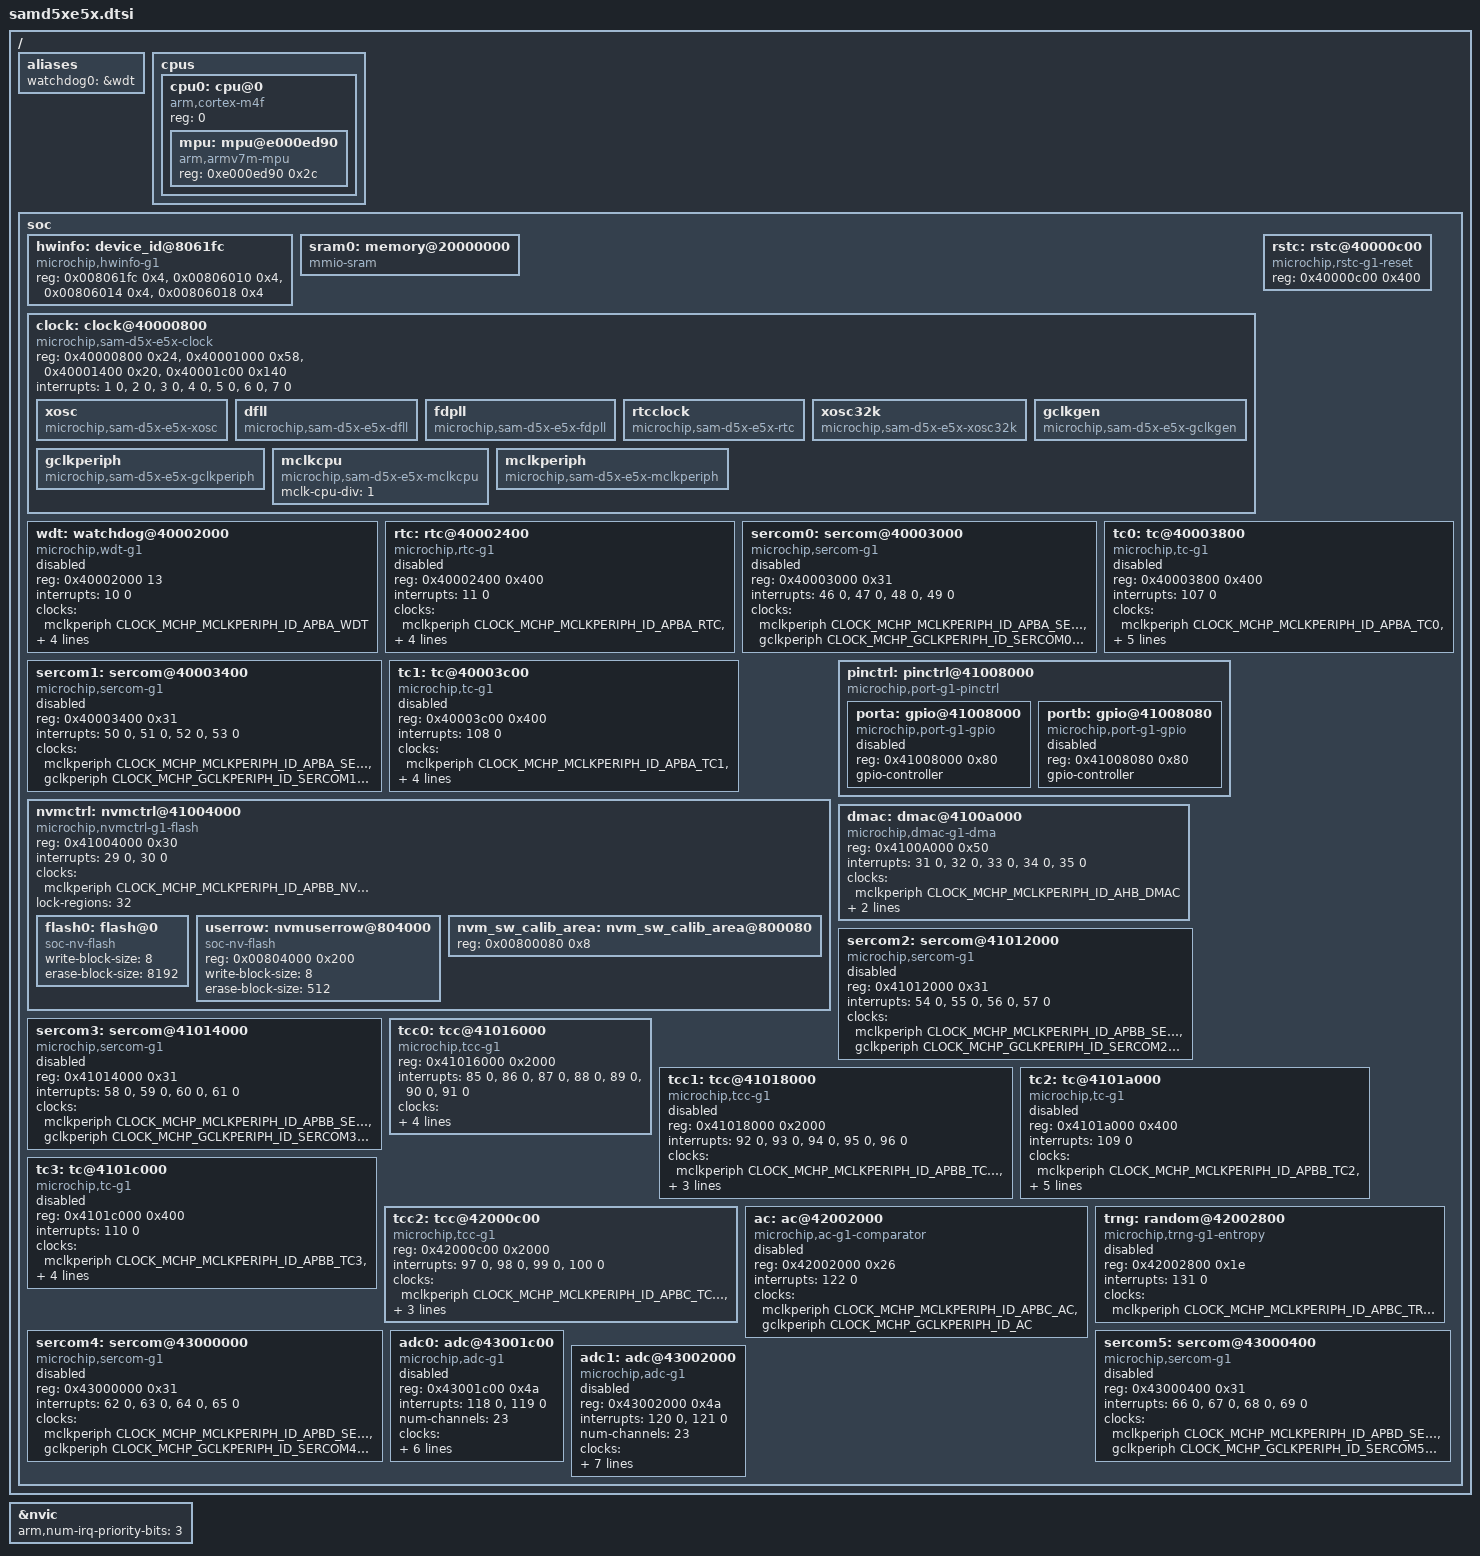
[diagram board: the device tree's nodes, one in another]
/*
 * Copyright (c) 2025-2026 Microchip Technology Inc.
 *
 * SPDX-License-Identifier: Apache-2.0
 */

#include <arm/armv7-m.dtsi>
#include <zephyr/dt-bindings/gpio/gpio.h>
#include <zephyr/dt-bindings/pwm/pwm.h>
#include <zephyr/dt-bindings/clock/mchp_sam_d5x_e5x_clock.h>

/ {
	aliases {
		watchdog0 = &wdt;
	};

	cpus {
		#address-cells = <1>;
		#size-cells = <0>;

		cpu0: cpu@0 {
			device_type = "cpu";
			compatible = "arm,cortex-m4f";
			reg = <0>;
			#address-cells = <1>;
			#size-cells = <1>;

			mpu: mpu@e000ed90 {
				compatible = "arm,armv7m-mpu";
				reg = <0xe000ed90 0x2c>;
			};
		};
	};

	soc {
		hwinfo: device_id@8061fc {
			compatible = "microchip,hwinfo-g1";
			reg = <0x008061fc 0x4>,
			      <0x00806010 0x4>,
			      <0x00806014 0x4>,
			      <0x00806018 0x4>;
		};

		sram0: memory@20000000 {
			compatible = "mmio-sram";
		};

		clock: clock@40000800 {
			compatible = "microchip,sam-d5x-e5x-clock";
			reg = <0x40000800 0x24>, <0x40001000 0x58>,
			      <0x40001400 0x20>, <0x40001c00 0x140>;
			reg-names = "mclk", "oscctrl",
				    "osc32kctrl", "gclk";
			interrupts = <1 0>, <2 0>, <3 0>, <4 0>,
				     <5 0>, <6 0>, <7 0>;
			interrupt-names = "mclk", "xosc0", "xosc1", "dfll",
					  "fdpll0", "fdpll1", "xosc32k";

			xosc: xosc {
				compatible = "microchip,sam-d5x-e5x-xosc";
			};

			dfll: dfll {
				compatible = "microchip,sam-d5x-e5x-dfll";
			};

			fdpll: fdpll {
				compatible = "microchip,sam-d5x-e5x-fdpll";
			};

			rtcclock: rtcclock {
				compatible = "microchip,sam-d5x-e5x-rtc";
				#clock-cells = <1>;
			};

			xosc32k: xosc32k {
				compatible = "microchip,sam-d5x-e5x-xosc32k";
			};

			gclkgen: gclkgen {
				compatible = "microchip,sam-d5x-e5x-gclkgen";
			};

			gclkperiph: gclkperiph {
				compatible = "microchip,sam-d5x-e5x-gclkperiph";
				#clock-cells = <1>;
			};

			mclkcpu: mclkcpu {
				compatible = "microchip,sam-d5x-e5x-mclkcpu";
				mclk-cpu-div = <1>;
			};

			mclkperiph: mclkperiph {
				compatible = "microchip,sam-d5x-e5x-mclkperiph";
				#clock-cells = <1>;
			};
		};

		rstc: rstc@40000c00 {
			compatible = "microchip,rstc-g1-reset";
			reg = <0x40000c00 0x400>;
		};

		wdt: watchdog@40002000 {
			compatible = "microchip,wdt-g1";
			reg = <0x40002000 13>;
			interrupts = <10 0>;
			interrupt-names = "wdt-ew";
			clocks = <&mclkperiph CLOCK_MCHP_MCLKPERIPH_ID_APBA_WDT>;
			clock-names = "mclk";
			max-installable-timeout-count = <1>;
			max-timeout-window = <0x4000>;	/* 16384 milliseconds */
			max-timeout-window-mode = <0x8000>;/* 32768 milliseconds */
			min-window-limit = <0x8>;/* 8 milliseconds */
			status = "disabled";
		};

		rtc: rtc@40002400 {
			compatible = "microchip,rtc-g1";
			reg = <0x40002400 0x400>;
			interrupts = <11 0>;
			clocks = <&mclkperiph CLOCK_MCHP_MCLKPERIPH_ID_APBA_RTC>,
				 <&rtcclock CLOCK_MCHP_RTC_ID>;
			clock-names = "mclk", "rtcclk";
			prescaler = <1>;
			alarms-count = <2>;
			cal-constant = <1048576>;
			status = "disabled";
		};

		sercom0: sercom@40003000 {
			compatible = "microchip,sercom-g1";
			status = "disabled";
			reg = <0x40003000 0x31>;
			interrupts = <46 0>, <47 0>, <48 0>, <49 0>;
			clocks = <&mclkperiph CLOCK_MCHP_MCLKPERIPH_ID_APBA_SERCOM0>,
				 <&gclkperiph CLOCK_MCHP_GCLKPERIPH_ID_SERCOM0_CORE>;
			clock-names = "mclk", "gclk";
		};

		sercom1: sercom@40003400 {
			compatible = "microchip,sercom-g1";
			status = "disabled";
			reg = <0x40003400 0x31>;
			interrupts = <50 0>, <51 0>, <52 0>, <53 0>;
			clocks = <&mclkperiph CLOCK_MCHP_MCLKPERIPH_ID_APBA_SERCOM1>,
				 <&gclkperiph CLOCK_MCHP_GCLKPERIPH_ID_SERCOM1_CORE>;
			clock-names = "mclk", "gclk";
		};

		tc0: tc@40003800 {
			compatible = "microchip,tc-g1";
			reg = <0x40003800 0x400>;
			interrupts = <107 0>;
			clocks = <&mclkperiph CLOCK_MCHP_MCLKPERIPH_ID_APBA_TC0>,
				 <&gclkperiph CLOCK_MCHP_GCLKPERIPH_ID_TC0>,
				 <&mclkperiph CLOCK_MCHP_MCLKPERIPH_ID_APBA_TC1>;
			clock-names = "mclk", "gclk", "client_mclk";
			max-bit-width = <16>;
			prescaler = <1>;
			channels = <2>;
			status = "disabled";
		};

		tc1: tc@40003c00 {
			compatible = "microchip,tc-g1";
			reg = <0x40003c00 0x400>;
			interrupts = <108 0>;
			clocks = <&mclkperiph CLOCK_MCHP_MCLKPERIPH_ID_APBA_TC1>,
				 <&gclkperiph CLOCK_MCHP_GCLKPERIPH_ID_TC1>;
			clock-names = "mclk", "gclk";
			max-bit-width = <16>;
			prescaler = <1>;
			channels = <2>;
			status = "disabled";
		};

		nvmctrl: nvmctrl@41004000 {
			compatible = "microchip,nvmctrl-g1-flash";
			status = "okay";
			reg = <0x41004000 0x30>;
			interrupts = <29 0>, <30 0>;
			clocks = <&mclkperiph CLOCK_MCHP_MCLKPERIPH_ID_APBB_NVMCTRL>;
			clock-names = "mclk";
			lock-regions = <32>;
			#address-cells = <1>;
			#size-cells = <1>;

			flash0: flash@0 {
				compatible = "soc-nv-flash";
				write-block-size = <8>;
				erase-block-size = <8192>;
			};

			userrow: nvmuserrow@804000 {
				compatible = "soc-nv-flash";
				reg = <0x00804000 0x200>;
				write-block-size = <8>;
				erase-block-size = <512>;
			};

			nvm_sw_calib_area: nvm_sw_calib_area@800080 {
				reg = <0x00800080 0x8>;
			};
		};

		pinctrl: pinctrl@41008000 {
			compatible = "microchip,port-g1-pinctrl";
			#address-cells = <1>;
			#size-cells = <1>;
			ranges = <0x41008000 0x41008000 0x200>;

			porta: gpio@41008000 {
				compatible = "microchip,port-g1-gpio";
				reg = <0x41008000 0x80>;
				gpio-controller;
				#gpio-cells = <2>;
				#microchip,pin-cells = <2>;
				status = "disabled";
			};

			portb: gpio@41008080 {
				compatible = "microchip,port-g1-gpio";
				reg = <0x41008080 0x80>;
				gpio-controller;
				#gpio-cells = <2>;
				#microchip,pin-cells = <2>;
				status = "disabled";
			};
		};

		dmac: dmac@4100a000 {
			compatible = "microchip,dmac-g1-dma";
			reg = <0x4100A000 0x50>;
			interrupts = <31 0>, <32 0>, <33 0>, <34 0>, <35 0>;
			clocks = <&mclkperiph CLOCK_MCHP_MCLKPERIPH_ID_AHB_DMAC>;
			clock-names = "mclk";
			dma-channels = <32>;
			dma-alignment = <16>;
			#dma-cells = <2>;
		};

		sercom2: sercom@41012000 {
			compatible = "microchip,sercom-g1";
			status = "disabled";
			reg = <0x41012000 0x31>;
			interrupts = <54 0>, <55 0>, <56 0>, <57 0>;
			clocks = <&mclkperiph CLOCK_MCHP_MCLKPERIPH_ID_APBB_SERCOM2>,
				 <&gclkperiph CLOCK_MCHP_GCLKPERIPH_ID_SERCOM2_CORE>;
			clock-names = "mclk", "gclk";
		};

		sercom3: sercom@41014000 {
			compatible = "microchip,sercom-g1";
			status = "disabled";
			reg = <0x41014000 0x31>;
			interrupts = <58 0>, <59 0>, <60 0>, <61 0>;
			clocks = <&mclkperiph CLOCK_MCHP_MCLKPERIPH_ID_APBB_SERCOM3>,
				 <&gclkperiph CLOCK_MCHP_GCLKPERIPH_ID_SERCOM3_CORE>;
			clock-names = "mclk", "gclk";
		};

		tcc0: tcc@41016000 {
			compatible = "microchip,tcc-g1";
			reg = <0x41016000 0x2000>;
			interrupts = <85 0>, <86 0>, <87 0>, <88 0>, <89 0>, <90 0>, <91 0>;
			clocks = <&mclkperiph CLOCK_MCHP_MCLKPERIPH_ID_APBB_TCC0>,
				 <&gclkperiph CLOCK_MCHP_GCLKPERIPH_ID_TCC0>;
			clock-names = "mclk", "gclk";
			max-bit-width = <24>;
			channels = <6>;
		};

		tcc1: tcc@41018000 {
			compatible = "microchip,tcc-g1";
			reg = <0x41018000 0x2000>;
			interrupts = <92 0>, <93 0>, <94 0>, <95 0>, <96 0>;
			clocks = <&mclkperiph CLOCK_MCHP_MCLKPERIPH_ID_APBB_TCC1>,
				 <&gclkperiph CLOCK_MCHP_GCLKPERIPH_ID_TCC1>;
			clock-names = "mclk", "gclk";
			max-bit-width = <24>;
			channels = <4>;
			status = "disabled";
		};

		tc2: tc@4101a000 {
			compatible = "microchip,tc-g1";
			reg = <0x4101a000 0x400>;
			interrupts = <109 0>;
			clocks = <&mclkperiph CLOCK_MCHP_MCLKPERIPH_ID_APBB_TC2>,
				 <&gclkperiph CLOCK_MCHP_GCLKPERIPH_ID_TC2>,
				 <&mclkperiph CLOCK_MCHP_MCLKPERIPH_ID_APBB_TC3>;
			clock-names = "mclk", "gclk", "client_mclk";
			max-bit-width = <16>;
			prescaler = <1>;
			channels = <2>;
			status = "disabled";
		};

		tc3: tc@4101c000 {
			compatible = "microchip,tc-g1";
			reg = <0x4101c000 0x400>;
			interrupts = <110 0>;
			clocks = <&mclkperiph CLOCK_MCHP_MCLKPERIPH_ID_APBB_TC3>,
				 <&gclkperiph CLOCK_MCHP_GCLKPERIPH_ID_TC3>;
			clock-names = "mclk", "gclk";
			max-bit-width = <16>;
			prescaler = <1>;
			channels = <2>;
			status = "disabled";
		};

		tcc2: tcc@42000c00 {
			compatible = "microchip,tcc-g1";
			reg = <0x42000c00 0x2000>;
			interrupts = <97 0>, <98 0>, <99 0>, <100 0>;
			clocks = <&mclkperiph CLOCK_MCHP_MCLKPERIPH_ID_APBC_TCC2>,
				 <&gclkperiph CLOCK_MCHP_GCLKPERIPH_ID_TCC2>;
			clock-names = "mclk", "gclk";
			max-bit-width = <16>;
			channels = <3>;
		};

		ac: ac@42002000 {
			compatible = "microchip,ac-g1-comparator";
			status = "disabled";
			reg = <0x42002000 0x26>;
			interrupts = <122 0>;
			clocks = <&mclkperiph CLOCK_MCHP_MCLKPERIPH_ID_APBC_AC>,
				 <&gclkperiph CLOCK_MCHP_GCLKPERIPH_ID_AC>;
			clock-names = "mclk", "gclk";
		};

		trng: random@42002800 {
			compatible = "microchip,trng-g1-entropy";
			reg = <0x42002800 0x1e>;
			interrupts = <131 0>;
			clocks = <&mclkperiph CLOCK_MCHP_MCLKPERIPH_ID_APBC_TRNG>;
			clock-names = "mclk";
			status = "disabled";
		};

		sercom4: sercom@43000000 {
			compatible = "microchip,sercom-g1";
			status = "disabled";
			reg = <0x43000000 0x31>;
			interrupts = <62 0>, <63 0>, <64 0>, <65 0>;
			clocks = <&mclkperiph CLOCK_MCHP_MCLKPERIPH_ID_APBD_SERCOM4>,
				 <&gclkperiph CLOCK_MCHP_GCLKPERIPH_ID_SERCOM4_CORE>;
			clock-names = "mclk", "gclk";
		};

		sercom5: sercom@43000400 {
			compatible = "microchip,sercom-g1";
			status = "disabled";
			reg = <0x43000400 0x31>;
			interrupts = <66 0>, <67 0>, <68 0>, <69 0>;
			clocks = <&mclkperiph CLOCK_MCHP_MCLKPERIPH_ID_APBD_SERCOM5>,
				 <&gclkperiph CLOCK_MCHP_GCLKPERIPH_ID_SERCOM5_CORE>;
			clock-names = "mclk", "gclk";
		};

		adc0: adc@43001c00 {
			compatible = "microchip,adc-g1";
			reg = <0x43001c00 0x4a>;
			interrupts = <118 0>, <119 0>;
			interrupt-names = "overrun", "resrdy";
			num-channels = <23>;
			#io-channel-cells = <1>;
			clocks = <&mclkperiph CLOCK_MCHP_MCLKPERIPH_ID_APBD_ADC0>,
				 <&gclkperiph CLOCK_MCHP_GCLKPERIPH_ID_ADC0>;
			clock-names = "mclk", "gclk";
			nvm-calib = <&nvm_sw_calib_area>;
			calib-mapping = <0 0x2 0x7>,
					<4 0x8 0x7>,
					<8 0x5 0x7>;
			calib-mapping-names = "BIASCOMP", "BIASR2R", "BIASREFBUF";
			status = "disabled";
		};

		adc1: adc@43002000 {
			compatible = "microchip,adc-g1";
			reg = <0x43002000 0x4a>;
			interrupts = <120 0>, <121 0>;
			interrupt-names = "overrun", "resrdy";
			num-channels = <23>;
			#io-channel-cells = <1>;
			clocks = <&mclkperiph CLOCK_MCHP_MCLKPERIPH_ID_APBD_ADC1>,
				 <&gclkperiph CLOCK_MCHP_GCLKPERIPH_ID_ADC1>;
			clock-names = "mclk", "gclk";
			nvm-calib = <&nvm_sw_calib_area>;
			calib-mapping = <0 0x10 0x7>,
					<4 0x16 0x7>,
					<8 0x13 0x7>;
			calib-mapping-names = "BIASCOMP", "BIASR2R", "BIASREFBUF";
			status = "disabled";
		};
	};
};

&nvic {
	arm,num-irq-priority-bits = <3>;
};
